# NM1500_v1 register map
File version: 1.0
Registers are 32-bit, read-write, reset 0x0 unless marked. A register's access mark holds for its fields unless they carry their own. Offsets are from the block's base; [hi:lo] are bit positions; 'fields as' and 'values as' point back to an identical list.

## ACMP — ACMP Register Map
Base 0x400D0000
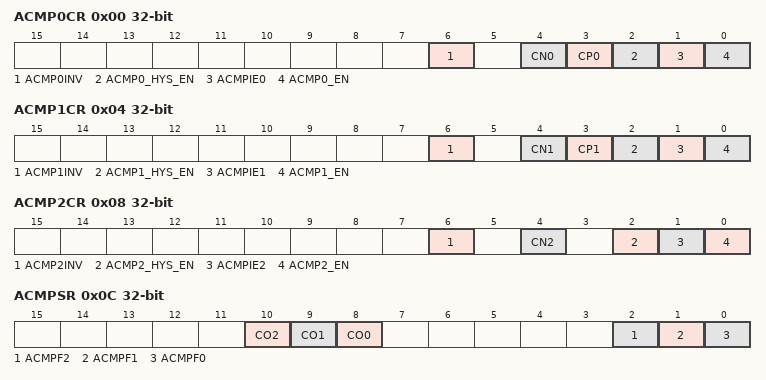
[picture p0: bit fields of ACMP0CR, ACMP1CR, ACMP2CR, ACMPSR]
0x00 ACMP0CR — Analog Comparator 0 Control Register
  [6] ACMP0INV — Analog Comparator 0 output inverse select
    0=The comparator output inverse function Disabled; 1=The comparator output inverse function Enabled
  [4] CN0 — Analog Comparator 0 negative input select
    0=The comparator reference pin P8.3/CPN0 is selected as the negative comparator input; 1=The internal comparator reference voltage (Vref=1.2V) is selected as the negative comparator input
  [3] CP0 — Analog Comparator 0 positive input select
    0=The comparator reference pin P8.4/CPP0 is selected as the positive comparator input; 1=The internal OP amplifier 0 output is selected as the positive comparator input
  [2] ACMP0_HYS_EN — CMP Hysteresis Enable
    0=Hysteresis function Disabled (Default); 1=Hysteresis function Enabled. The typical range is 20mV
  [1] ACMPIE0 — Analog Comparator 0 Interrupt Enable
    0=Interrupt function Disabled; 1=Interrupt function Enabled
  [0] ACMP0_EN — Analog Comparator 0 Enable. Comparator output need wait stable 10 us after ACMP0_EN is set.
    0=Disabled; 1=Enabled
0x04 ACMP1CR — Analog Comparator 1 Control Register
  [6] ACMP1INV — Analog Comparator 1 output inverse select
    values as ACMP0CR.ACMP0INV
  [4] CN1 — Analog Comparator 1 negative input select
    0=The comparator reference pin P6.4/CPN1 is selected as the negative comparator input; 1=The internal comparator reference voltage (Vref=1.2V) is selected as the negative comparator input
  [3] CP1 — Analog Comparator 1 positive input select
    0=The comparator reference pin P6.5/CPP1 is selected as the positive comparator input; 1=The internal OP amplifier 1 output is selected as the positive comparator input
  [2] ACMP1_HYS_EN — CMP Hysteresis Enable
    values as ACMP0CR.ACMP0_HYS_EN
  [1] ACMPIE1 — Analog Comparator 1 Interrupt Enable
    0=Interrupt function Disabled; 1=Interrupt function Enabled
  [0] ACMP1_EN — Analog Comparator 1 Enable. Comparator output need wait stable 10 us after ACMP1_EN is set.
    0=Disabled; 1=Enabled
0x08 ACMP2CR — Analog Comparator 2 Control Register
  [6] ACMP2INV — Analog Comparator 2 output inverse select
    values as ACMP0CR.ACMP0INV
  [4] CN2 — Analog Comparator 2 negative input select
    0=The comparator reference pin P7.4/CPN2 is selected as the negative comparator input; 1=The internal comparator reference voltage (Vref=1.2V) is selected as the negative comparator input
  [2] ACMP2_HYS_EN — CMP Hysteresis Enable
    values as ACMP0CR.ACMP0_HYS_EN
  [1] ACMPIE2 — Analog Comparator 2 Interrupt Enable
    0=Interrupt function Disabled; 1=Interrupt function Enabled
  [0] ACMP2_EN — Analog Comparator 2 Enable. Comparator output need wait stable 10 us after ACMP2_EN is first set.
    0=Disabled; 1=Enabled
0x0C ACMPSR — Analog Comparator Status Register
  [10] CO2 — Compare 2 Output
  [9] CO1 — Compare 1 Output
  [8] CO0 — Compare 0 Output
  [2] ACMPF2 — Compare 2 Flag. This bit is set by hardware whenever the comparator 2 output changes state. This will cause an interrupt if ACMPCR2[1] is set to 1. Write 1 to clear this bit to 0.
  [1] ACMPF1 — Compare 1 Flag. This bit is set by hardware whenever the comparator 1 output changes state. This will cause an interrupt if ACMPCR1[1] is set to 1. Write 1 to clear this bit to 0.
  [0] ACMPF0 — Compare 0 Flag. This bit is set by hardware whenever the comparator 0 output changes state. This will cause an interrupt if ACMPCR0[1] is set to 1. Write 1 to clear this bit to 0.

## OPA — OPA Register Map
Base 0x400F0000
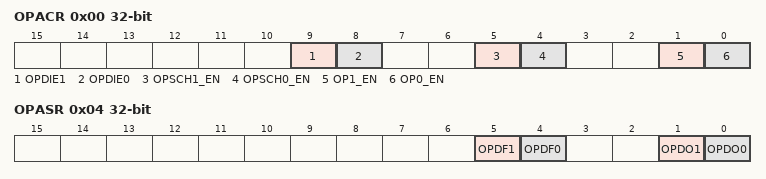
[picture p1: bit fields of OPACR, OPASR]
0x00 OPACR — OP Amplifier Control Register
  [9] OPDIE1 — OP Amplifier 1 Schmitt Trigger Digital Output Interrupt Enable. The OPDF1 interrupt flag is set by hardware whenever the OP amplifier 1 Schmitt trigger non-inverting buffer digital output changes state, in the meanwhile, if OPDIE1 is set to 1, a comparator interrupt request is generated.
    0=OP Amplifier 1 digital output interrupt function Disabled; 1=OP Amplifier 1 digital output interrupt function Enabled
  [8] OPDIE0 — OP Amplifier 0 Schmitt Trigger Digital Output Interrupt Enable. The OPDF0 interrupt flag is set by hardware whenever the OP amplifier 0 Schmitt trigger non-inverting buffer digital output changes state, in the meanwhile, if OPDIE0 is set to 1, a comparator interrupt request is generated.
    0=OP Amplifier 0 digital output interrupt function Disabled; 1=OP Amplifier 0 digital output interrupt function Enabled
  [5] OPSCH1_EN — OP Amplifier 1 Schmitt Trigger Non-inverting Buffer Enable
    0=Disabled; 1=Enabled
  [4] OPSCH0_EN — OP Amplifier 0 Schmitt Trigger Non-inverting Buffer Enable
    0=Disabled; 1=Enabled
  [1] OP1_EN — OP Amplifier 1 Enable. The OP Amplifier 1 output needs to wait stable 20 s after OP1_EN is first set.
    0=OP Amplifier 1 Disabled; 1=OP Amplifier 1 Enabled
  [0] OP0_EN — OP Amplifier 0 Enable. The OP Amplifier 0 output needs to wait stable 20 s after OP0_EN is first set.
    0=OP Amplifier 0 Disabled; 1=OP Amplifier 0 Enabled
0x04 OPASR — OP Amplifier Status Register
  [5] OPDF1 — OP Amplifier 1 Schmitt Trigger Digital Output Interrupt Flag. OPDF1 interrupt flag is set by hardware whenever the OP amplifier 1 Schmitt trigger non-inverting buffer digital output changes state. This bit is cleared by writing 1 to itself.
  [4] OPDF0 — OP Amplifier 0 Schmitt Trigger Digital Output Interrupt Flag. OPDF0 interrupt flag is set by hardware whenever the OP amplifier 0 Schmitt trigger non-inverting buffer digital output changes state. This bit is cleared by writing 1 to itself.
  [1] OPDO1 — OP Amplifier 1 Digital Output
  [0] OPDO0 — OP Amplifier 0 Digital Output
